VERSION ""

NS_ :

BS_:

BU_:

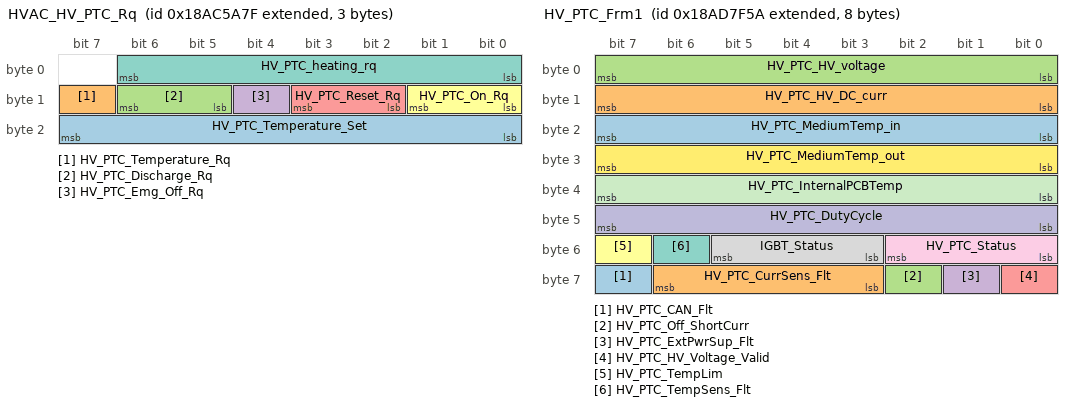
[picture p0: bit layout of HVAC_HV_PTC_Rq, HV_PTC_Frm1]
BO_ 2561432191 HVAC_HV_PTC_Rq: 3 ECU
 SG_ HV_PTC_Temperature_Set : 16|8@1+ (1,-50) [-50.0|204.0] "" Vector__XXX
 SG_ HV_PTC_Temperature_Rq : 15|1@1+ (1,0) [0.0|1.0] "" Vector__XXX
 SG_ HV_PTC_Discharge_Rq : 13|2@1+ (1,0) [0.0|3.0] "" Vector__XXX
 SG_ HV_PTC_Emg_Off_Rq : 12|1@1+ (1,0) [0.0|1.0] "" Vector__XXX
 SG_ HV_PTC_Reset_Rq : 10|2@1+ (1,0) [0.0|3.0] "" Vector__XXX
 SG_ HV_PTC_On_Rq : 8|2@1+ (1,0) [0.0|3.0] "" Vector__XXX
 SG_ HV_PTC_heating_rq : 0|7@1+ (1,0) [0.0|100.0] "%" Vector__XXX

BO_ 2561507162 HV_PTC_Frm1: 8 ECU
 SG_ HV_PTC_CAN_Flt : 63|1@1+ (1,0) [0.0|1.0] "" Vector__XXX
 SG_ HV_PTC_CurrSens_Flt : 59|4@1+ (1,0) [0.0|16.0] "" Vector__XXX
 SG_ HV_PTC_Off_ShortCurr : 58|1@1+ (1,0) [0.0|1.0] "" Vector__XXX
 SG_ HV_PTC_ExtPwrSup_Flt : 57|1@1+ (1,0) [0.0|1.0] "" Vector__XXX
 SG_ HV_PTC_HV_Voltage_Valid : 56|1@1+ (1,0) [0.0|1.0] "" Vector__XXX
 SG_ HV_PTC_TempLim : 55|1@1+ (1,0) [0.0|1.0] "" Vector__XXX
 SG_ HV_PTC_TempSens_Flt : 54|1@1+ (1,0) [0.0|1.0] "" Vector__XXX
 SG_ IGBT_Status : 51|3@1+ (1,0) [0.0|7.0] "" Vector__XXX
 SG_ HV_PTC_Status : 48|3@1+ (1,0) [0.0|7.0] "" Vector__XXX
 SG_ HV_PTC_DutyCycle : 40|8@1+ (1,-50) [0.0|100.0] "%" Vector__XXX
 SG_ HV_PTC_InternalPCBTemp : 32|8@1+ (1,-50) [-50.0|204.0] "" Vector__XXX
 SG_ HV_PTC_MediumTemp_out : 24|8@1+ (1,-50) [-50.0|204.0] "" Vector__XXX
 SG_ HV_PTC_MediumTemp_in : 16|8@1+ (1,-50) [-50.0|204.0] "" Vector__XXX
 SG_ HV_PTC_HV_DC_curr : 8|8@1+ (0.25,0.0) [0.0|63.5] "A" Vector__XXX
 SG_ HV_PTC_HV_voltage : 0|8@1+ (3,0) [0.0|765.0] "V" Vector__XXX

BO_ 2561467533 HVAC_HV_PTC_Rq2: 8 ECU
 SG_ HV_PTC_SW_Version_Rq : 0|8@1+ (1,0) [0.0|255.0] "" Vector__XXX

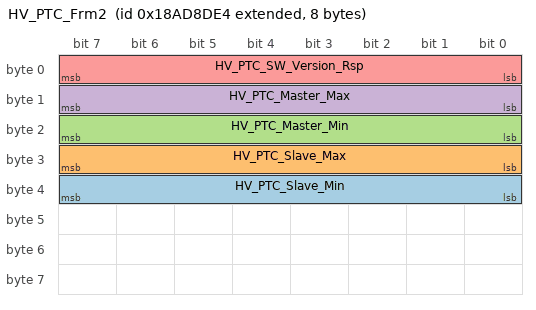
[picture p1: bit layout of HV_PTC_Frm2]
BO_ 2561510884 HV_PTC_Frm2: 8 ECU
 SG_ HV_PTC_Slave_Min : 32|8@1+ (1,0) [0.0|255.0] "" Vector__XXX
 SG_ HV_PTC_Slave_Max : 24|8@1+ (1,0) [0.0|255.0] "" Vector__XXX
 SG_ HV_PTC_Master_Min : 16|8@1+ (1,0) [0.0|255.0] "" Vector__XXX
 SG_ HV_PTC_Master_Max : 8|8@1+ (1,0) [0.0|255.0] "" Vector__XXX
 SG_ HV_PTC_SW_Version_Rsp : 0|8@1+ (1,0) [0.0|255.0] "" Vector__XXX

CM_ BO_ 2561432191 "Receive Commands";
CM_ SG_ 2561432191 HV_PTC_Temperature_Set "The value of target temperature";
CM_ SG_ 2561432191 HV_PTC_Temperature_Rq "Temperature control mode Request";
CM_ SG_ 2561432191 HV_PTC_Discharge_Rq "Discharge Request";
CM_ SG_ 2561432191 HV_PTC_Emg_Off_Rq "Emergency Shutdown";
CM_ SG_ 2561432191 HV_PTC_Reset_Rq "Reset Request";
CM_ SG_ 2561432191 HV_PTC_On_Rq "PTC
Enable HV-PTC";
CM_ SG_ 2561432191 HV_PTC_heating_rq "Percentage of Heating Power Request";
CM_ BO_ 2561507162 "Feedback info";
CM_ SG_ 2561507162 HV_PTC_CAN_Flt "CAN communication error Indicator";
CM_ SG_ 2561507162 HV_PTC_CurrSens_Flt "Current sensor fault";
CM_ SG_ 2561507162 HV_PTC_Off_ShortCurr "Short- circuit detected";
CM_ SG_ 2561507162 HV_PTC_ExtPwrSup_Flt "External Power Supply failure";
CM_ SG_ 2561507162 HV_PTC_HV_Voltage_Valid "HV Valid Indicator";
CM_ SG_ 2561507162 HV_PTC_TempLim "Over temperature Indicator";
CM_ SG_ 2561507162 HV_PTC_TempSens_Flt "temperature sensor fault";
CM_ SG_ 2561507162 IGBT_Status "IGBT
IGBT Status signals";
CM_ SG_ 2561507162 HV_PTC_Status "HV-PTC 
HV-PTC Status signals";
CM_ SG_ 2561507162 HV_PTC_DutyCycle "PTC
HV_PTC Duty Cycle";
CM_ SG_ 2561507162 HV_PTC_InternalPCBTemp "PCB 
PCB Temperature";
CM_ SG_ 2561507162 HV_PTC_MediumTemp_out "Medium Temperature at the outlet";
CM_ SG_ 2561507162 HV_PTC_MediumTemp_in "Medium Temperature at the inlet";
CM_ SG_ 2561507162 HV_PTC_HV_DC_curr "PTC
Current Draw of HV-PTC";
CM_ SG_ 2561507162 HV_PTC_HV_voltage "High Voltage Measurement";
CM_ BO_ 2561467533 "Receive command";
CM_ SG_ 2561467533 HV_PTC_SW_Version_Rq "Rquest for software version";
CM_ BO_ 2561510884 "Feedback info";
CM_ SG_ 2561510884 HV_PTC_Slave_Min "Minor version number of the slave software";
CM_ SG_ 2561510884 HV_PTC_Slave_Max "Major version number of the slave software";
CM_ SG_ 2561510884 HV_PTC_Master_Min "Minor version number of the master software";
CM_ SG_ 2561510884 HV_PTC_Master_Max "Major version number of the master software";
CM_ SG_ 2561510884 HV_PTC_SW_Version_Rsp "Output software version";
BA_DEF_ BO_  "GenMsgCycleTime" INT 0 65535;
BA_DEF_DEF_  "GenMsgCycleTime" 0;
BA_ "GenMsgCycleTime" BO_ 2561432191 1000.0;
BA_ "GenMsgCycleTime" BO_ 2561507162 1000.0;
BA_ "GenMsgCycleTime" BO_ 2561467533 100;
BA_ "GenMsgCycleTime" BO_ 2561510884 100;
